# SAM3U1E register map
File version: 0
Registers are 32-bit, read-write, reset 0x0 unless marked. A register's access mark holds for its fields unless they carry their own. Offsets are from the block's base; [hi:lo] are bit positions; {n}, {i} and the like mark numbered series.

## DMAC — DMA Controller
Base 0x400B0000; register names take the prefix DMAC_
0x00 GCFG reset 0x10 — DMAC Global Configuration Register
  [4] ARB_CFG
0x04 EN — DMAC Enable Register
  [0] ENABLE
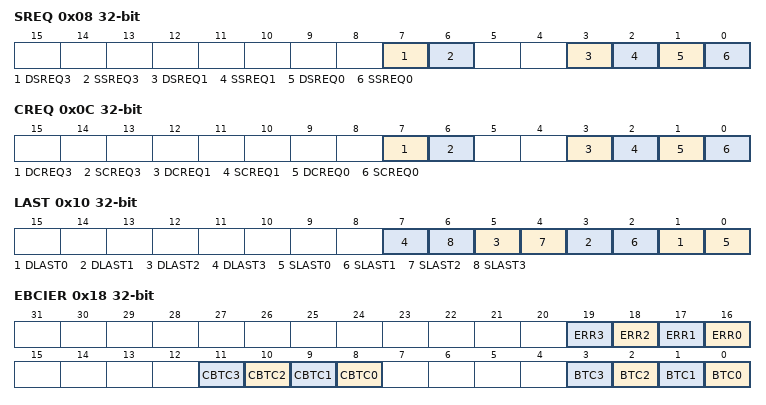
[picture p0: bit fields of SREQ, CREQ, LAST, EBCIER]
0x08 SREQ — DMAC Software Single Request Register
  [7] DSREQ3, [6] SSREQ3, [3] DSREQ1, [2] SSREQ1, [1] DSREQ0, [0] SSREQ0
0x0C CREQ — DMAC Software Chunk Transfer Request Register
  [7] DCREQ3, [6] SCREQ3, [3] DCREQ1, [2] SCREQ1, [1] DCREQ0, [0] SCREQ0
0x10 LAST — DMAC Software Last Transfer Flag Register
  [2n+1] DLAST{n} (n=0..3), [2n] SLAST{n} (n=0..3)
0x18 EBCIER wo reset not defined — DMAC Error, Chained Buffer transfer completed and Buffer transfer completed Interrupt Enable register.
  [n+16] ERR{n} (n=0..3), [n+8] CBTC{n} (n=0..3), [n] BTC{n} (n=0..3)
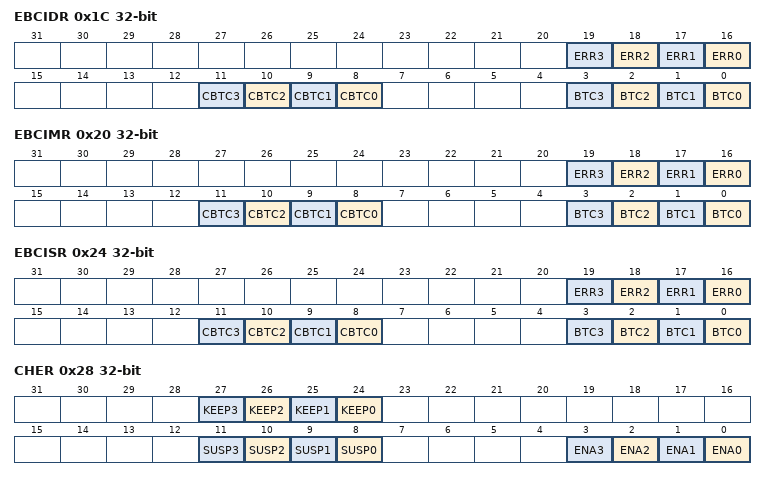
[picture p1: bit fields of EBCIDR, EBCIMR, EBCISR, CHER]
0x1C EBCIDR wo reset not defined — DMAC Error, Chained Buffer transfer completed and Buffer transfer completed Interrupt Disable register.
  [n+16] ERR{n} (n=0..3), [n+8] CBTC{n} (n=0..3), [n] BTC{n} (n=0..3)
0x20 EBCIMR ro — DMAC Error, Chained Buffer transfer completed and Buffer transfer completed Mask Register.
  [n+16] ERR{n} (n=0..3), [n+8] CBTC{n} (n=0..3), [n] BTC{n} (n=0..3)
0x24 EBCISR ro — DMAC Error, Chained Buffer transfer completed and Buffer transfer completed Status Register.
  [n+16] ERR{n} (n=0..3), [n+8] CBTC{n} (n=0..3), [n] BTC{n} (n=0..3)
0x28 CHER wo reset not defined — DMAC Channel Handler Enable Register
  [n+24] KEEP{n} (n=0..3), [n+8] SUSP{n} (n=0..3), [n] ENA{n} (n=0..3)
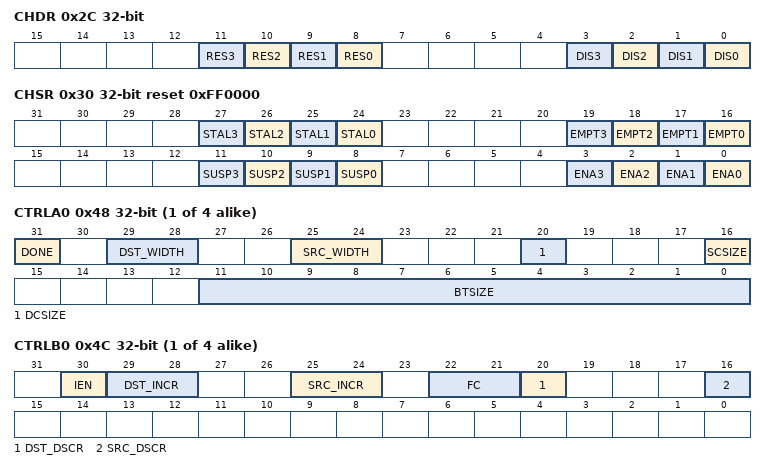
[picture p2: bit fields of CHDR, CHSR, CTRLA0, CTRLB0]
0x2C CHDR wo reset not defined — DMAC Channel Handler Disable Register
  [n+8] RES{n} (n=0..3), [n] DIS{n} (n=0..3)
0x30 CHSR ro reset 0xFF0000 — DMAC Channel Handler Status Register
  [n+24] STAL{n} (n=0..3), [n+16] EMPT{n} (n=0..3), [n+8] SUSP{n} (n=0..3), [n] ENA{n} (n=0..3)
{0x3C+0x28*i} SADDR{i} (i=0..3) — DMAC Channel Source Address Register (ch_num = {i})
  [31:0] SADDRx
{0x40+0x28*i} DADDR{i} (i=0..3) — DMAC Channel Destination Address Register (ch_num = {i})
  [31:0] DADDRx
{0x44+0x28*i} DSCR{i} (i=0..3) — DMAC Channel Descriptor Address Register (ch_num = {i})
  [31:2] DSCRx
{0x48+0x28*i} CTRLA{i} (i=0..3) — DMAC Channel Control A Register (ch_num = {i})
  [31] DONE, [29:28] DST_WIDTH, [25:24] SRC_WIDTH, [20] DCSIZE, [16] SCSIZE, [11:0] BTSIZE
{0x4C+0x28*i} CTRLB{i} (i=0..3) — DMAC Channel Control B Register (ch_num = {i})
  [30] IEN, [29:28] DST_INCR, [25:24] SRC_INCR, [22:21] FC, [20] DST_DSCR, [16] SRC_DSCR
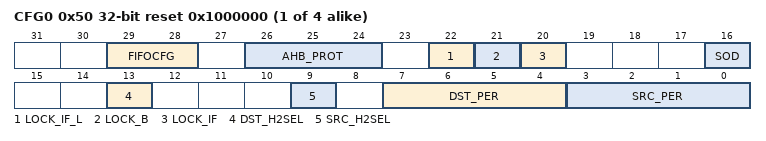
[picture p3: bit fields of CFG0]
{0x50+0x28*i} CFG{i} reset 0x1000000 (i=0..3) — DMAC Channel Configuration Register (ch_num = {i})
  [29:28] FIFOCFG, [26:24] AHB_PROT, [22] LOCK_IF_L, [21] LOCK_B, [20] LOCK_IF, [16] SOD, [13] DST_H2SEL, [9] SRC_H2SEL, [7:4] DST_PER, [3:0] SRC_PER

## MATRIX — AHB Bus Matrix
Base 0x400E0200; register names take the prefix MATRIX_
{0x0+4i} MCFG{i} (i=0..4) reset not defined — Master Configuration Register
  [2:0] ULBT — Undefined Length Burst Type
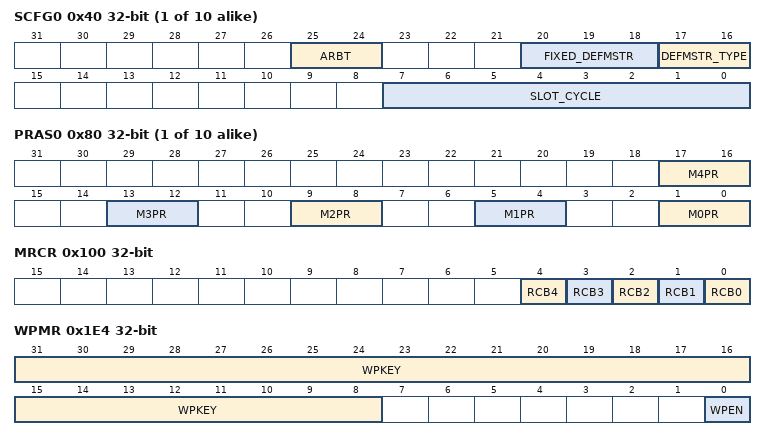
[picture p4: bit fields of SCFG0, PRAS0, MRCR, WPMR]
{0x40+4i} SCFG{i} (i=0..9) reset not defined — Slave Configuration Register
  [25:24] ARBT — Arbitration Type
  [20:18] FIXED_DEFMSTR — Fixed Default Master
  [17:16] DEFMSTR_TYPE — Default Master Type
  [7:0] SLOT_CYCLE — Maximum Number of Allowed Cycles for a Burst
{0x80+8i} PRAS{i} (i=0..9) — Priority Register A for Slave {i}
  [4n+1:4n] M{n}PR (n=0..4) — Master {n} Priority
0x100 MRCR — Master Remap Control Register
  [n] RCB{n} (n=0..4) — Remap Command Bit for AHB Master {n}
0x1E4 WPMR — Write Protect Mode Register
  [31:8] WPKEY — Write Protect KEY (Write-only)
  [0] WPEN — Write Protect ENable
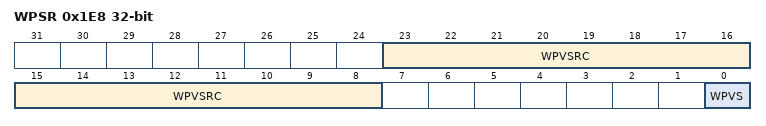
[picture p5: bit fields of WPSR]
0x1E8 WPSR ro — Write Protect Status Register
  [23:8] WPVSRC — Write Protect Violation Source
  [0] WPVS — Write Protect Violation Status

## UART — Universal Asynchronous Receiver Transmitter
Base 0x400E0600; register names take the prefix UART_
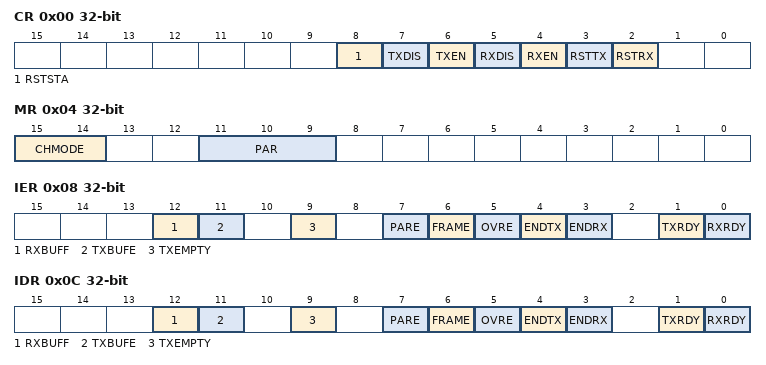
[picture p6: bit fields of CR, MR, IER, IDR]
0x00 CR wo reset not defined — Control Register
  [8] RSTSTA — Reset Status Bits
  [7] TXDIS — Transmitter Disable
  [6] TXEN — Transmitter Enable
  [5] RXDIS — Receiver Disable
  [4] RXEN — Receiver Enable
  [3] RSTTX — Reset Transmitter
  [2] RSTRX — Reset Receiver
0x04 MR — Mode Register
  [15:14] CHMODE — Channel Mode
    0=NORMAL (Normal Mode); 1=AUTOMATIC (Automatic Echo); 2=LOCAL_LOOPBACK; 3=REMOTE_LOOPBACK
  [11:9] PAR — Parity Type
    0=EVEN (Even parity); 1=ODD (Odd parity); 2=SPACE (Space: parity forced to 0); 3=MARK (Mark: parity forced to 1); 4=NO (No parity)
0x08 IER wo reset not defined — Interrupt Enable Register
  [12] RXBUFF — Enable Buffer Full Interrupt
  [11] TXBUFE — Enable Buffer Empty Interrupt
  [9] TXEMPTY — Enable TXEMPTY Interrupt
  [7] PARE — Enable Parity Error Interrupt
  [6] FRAME — Enable Framing Error Interrupt
  [5] OVRE — Enable Overrun Error Interrupt
  [4] ENDTX — Enable End of Transmit Interrupt
  [3] ENDRX — Enable End of Receive Transfer Interrupt
  [1] TXRDY — Enable TXRDY Interrupt
  [0] RXRDY — Enable RXRDY Interrupt
0x0C IDR wo reset not defined — Interrupt Disable Register
  [12] RXBUFF — Disable Buffer Full Interrupt
  [11] TXBUFE — Disable Buffer Empty Interrupt
  [9] TXEMPTY — Disable TXEMPTY Interrupt
  [7] PARE — Disable Parity Error Interrupt
  [6] FRAME — Disable Framing Error Interrupt
  [5] OVRE — Disable Overrun Error Interrupt
  [4] ENDTX — Disable End of Transmit Interrupt
  [3] ENDRX — Disable End of Receive Transfer Interrupt
  [1] TXRDY — Disable TXRDY Interrupt
  [0] RXRDY — Disable RXRDY Interrupt
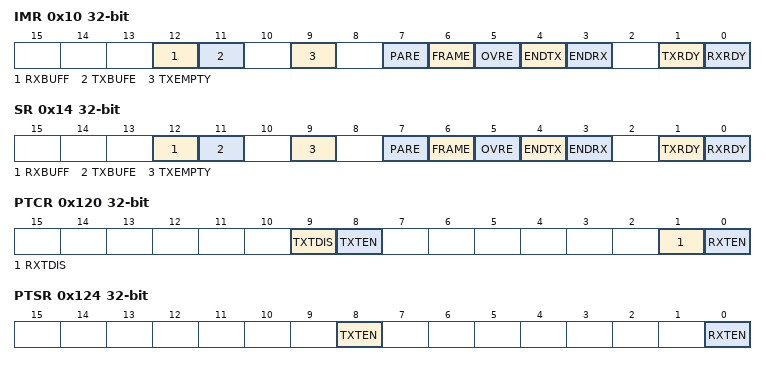
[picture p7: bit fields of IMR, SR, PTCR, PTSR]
0x10 IMR ro — Interrupt Mask Register
  [12] RXBUFF — Mask RXBUFF Interrupt
  [11] TXBUFE — Mask TXBUFE Interrupt
  [9] TXEMPTY — Mask TXEMPTY Interrupt
  [7] PARE — Mask Parity Error Interrupt
  [6] FRAME — Mask Framing Error Interrupt
  [5] OVRE — Mask Overrun Error Interrupt
  [4] ENDTX — Mask End of Transmit Interrupt
  [3] ENDRX — Mask End of Receive Transfer Interrupt
  [1] TXRDY — Disable TXRDY Interrupt
  [0] RXRDY — Mask RXRDY Interrupt
0x14 SR ro reset not defined — Status Register
  [12] RXBUFF — Receive Buffer Full
  [11] TXBUFE — Transmission Buffer Empty
  [9] TXEMPTY — Transmitter Empty
  [7] PARE — Parity Error
  [6] FRAME — Framing Error
  [5] OVRE — Overrun Error
  [4] ENDTX — End of Transmitter Transfer
  [3] ENDRX — End of Receiver Transfer
  [1] TXRDY — Transmitter Ready
  [0] RXRDY — Receiver Ready
0x18 RHR ro — Receive Holding Register
  [7:0] RXCHR — Received Character
0x1C THR wo reset not defined — Transmit Holding Register
  [7:0] TXCHR — Character to be Transmitted
0x20 BRGR — Baud Rate Generator Register
  [15:0] CD — Clock Divisor
0x100 RPR — Receive Pointer Register
  [31:0] RXPTR
0x104 RCR — Receive Counter Register
  [15:0] RXCTR
0x108 TPR — Transmit Pointer Register
  [31:0] TXPTR — Transmit Counter Register
0x10C TCR — Transmit Counter Register
  [15:0] TXCTR
0x110 RNPR — Receive Next Pointer Register
  [31:0] RXNPTR — Receive Next Pointer
0x114 RNCR — Receive Next Counter Register
  [15:0] RXNCTR — Receive Next Counter
0x118 TNPR — Transmit Next Pointer Register
  [31:0] TXNPTR — Transmit Next Pointer
0x11C TNCR — Transmit Next Counter Register
  [15:0] TXNCTR — Transmit Counter Next
0x120 PTCR wo — Transfer Control Register
  [9] TXTDIS — Transmitter Transfer Disable
  [8] TXTEN — Transmitter Transfer Enable
  [1] RXTDIS — Receiver Transfer Disable
  [0] RXTEN — Receiver Transfer Enable
0x124 PTSR ro — Transfer Status Register
  [8] TXTEN — Transmitter Transfer Enable
  [0] RXTEN — Receiver Transfer Enable
